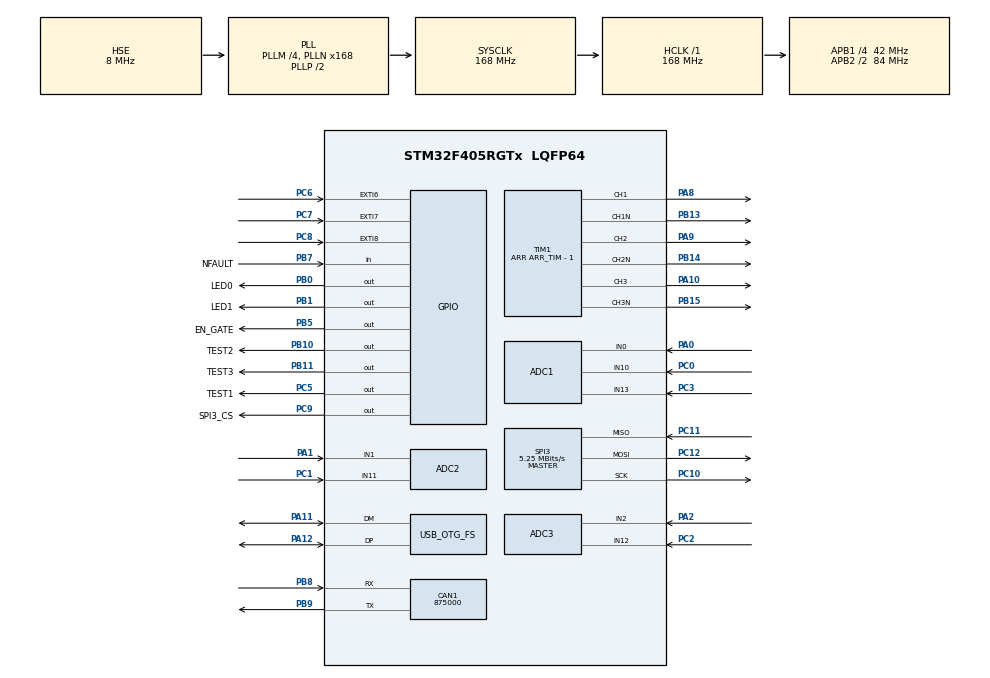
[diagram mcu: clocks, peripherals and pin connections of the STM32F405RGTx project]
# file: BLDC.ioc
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ADC1.Channel-0\#ChannelRegularConversion=ADC_CHANNEL_13
ADC1.Channel-1\#ChannelInjectedConversion=ADC_CHANNEL_10
ADC1.Channel-4\#ChannelInjectedConversion=ADC_CHANNEL_0
ADC1.ContinuousConvMode=ENABLE
ADC1.DMAContinuousRequests=ENABLE
ADC1.ExternalTrigInjecConv=ADC_EXTERNALTRIGINJECCONV_T1_TRGO
ADC1.InjNumberOfConversion=2
ADC1.InjectedOffset-1\#ChannelInjectedConversion=0
ADC1.InjectedOffset-4\#ChannelInjectedConversion=0
ADC1.InjectedRank-1\#ChannelInjectedConversion=1
ADC1.InjectedRank-4\#ChannelInjectedConversion=2
ADC1.Mode=ADC_TRIPLEMODE_INJECSIMULT
ADC1.NbrOfConversion=1
ADC1.NbrOfConversionFlag=1
ADC1.Rank-0\#ChannelRegularConversion=1
ADC1.SamplingTime-0\#ChannelRegularConversion=ADC_SAMPLETIME_480CYCLES
ADC1.SamplingTime-1\#ChannelInjectedConversion=ADC_SAMPLETIME_15CYCLES
ADC1.SamplingTime-4\#ChannelInjectedConversion=ADC_SAMPLETIME_15CYCLES
ADC1.master=1
ADC2.Channel-0\#ChannelRegularConversion=ADC_CHANNEL_1
ADC2.Channel-1\#ChannelInjectedConversion=ADC_CHANNEL_11
ADC2.Channel-4\#ChannelInjectedConversion=ADC_CHANNEL_1
ADC2.InjNumberOfConversion=2
ADC2.InjectedOffset-1\#ChannelInjectedConversion=0
ADC2.InjectedOffset-4\#ChannelInjectedConversion=0
ADC2.InjectedRank-1\#ChannelInjectedConversion=1
ADC2.InjectedRank-4\#ChannelInjectedConversion=2
ADC2.Mode=ADC_TRIPLEMODE_INJECSIMULT
ADC2.NbrOfConversion=1
ADC2.NbrOfConversionFlag=1
ADC2.Rank-0\#ChannelRegularConversion=1
ADC2.SamplingTime-0\#ChannelRegularConversion=ADC_SAMPLETIME_3CYCLES
ADC2.SamplingTime-1\#ChannelInjectedConversion=ADC_SAMPLETIME_15CYCLES
ADC2.SamplingTime-4\#ChannelInjectedConversion=ADC_SAMPLETIME_15CYCLES
ADC3.Channel-1\#ChannelRegularConversion=ADC_CHANNEL_2
ADC3.Channel-2\#ChannelInjectedConversion=ADC_CHANNEL_12
ADC3.Channel-3\#ChannelInjectedConversion=ADC_CHANNEL_2
ADC3.DMAContinuousRequests=DISABLE
ADC3.InjNumberOfConversion=2
ADC3.InjectedOffset-2\#ChannelInjectedConversion=0
ADC3.InjectedOffset-3\#ChannelInjectedConversion=0
ADC3.InjectedRank-2\#ChannelInjectedConversion=1
ADC3.InjectedRank-3\#ChannelInjectedConversion=2
ADC3.NbrOfConversionFlag=1
ADC3.Rank-1\#ChannelRegularConversion=1
ADC3.SamplingTime-1\#ChannelRegularConversion=ADC_SAMPLETIME_84CYCLES
ADC3.SamplingTime-2\#ChannelInjectedConversion=ADC_SAMPLETIME_15CYCLES
ADC3.SamplingTime-3\#ChannelInjectedConversion=ADC_SAMPLETIME_15CYCLES
CAN1.CalculateBaudRate=875000
CAN1.CalculateTimeBit=1142
CAN1.CalculateTimeQuantum=380.95238095238096
Dma.ADC1.1.Direction=DMA_PERIPH_TO_MEMORY
Dma.ADC1.1.FIFOMode=DMA_FIFOMODE_DISABLE
Dma.ADC1.1.Instance=DMA2_Stream4
Dma.ADC1.1.MemDataAlignment=DMA_MDATAALIGN_HALFWORD
Dma.ADC1.1.MemInc=DMA_MINC_ENABLE
Dma.ADC1.1.Mode=DMA_CIRCULAR
Dma.ADC1.1.PeriphDataAlignment=DMA_PDATAALIGN_HALFWORD
Dma.ADC1.1.PeriphInc=DMA_PINC_DISABLE
Dma.ADC1.1.Priority=DMA_PRIORITY_LOW
Dma.ADC3.0.Direction=DMA_PERIPH_TO_MEMORY
Dma.ADC3.0.FIFOMode=DMA_FIFOMODE_DISABLE
Dma.ADC3.0.Instance=DMA2_Stream0
Dma.ADC3.0.MemDataAlignment=DMA_MDATAALIGN_HALFWORD
Dma.ADC3.0.MemInc=DMA_MINC_ENABLE
Dma.ADC3.0.Mode=DMA_CIRCULAR
Dma.ADC3.0.PeriphDataAlignment=DMA_PDATAALIGN_HALFWORD
Dma.ADC3.0.PeriphInc=DMA_PINC_DISABLE
Dma.ADC3.0.Priority=DMA_PRIORITY_LOW
Dma.Request0=ADC3
Dma.Request1=ADC1
FREERTOS.Tasks01=Task01,24,256,StartTask01,As weak,NULL,Dynamic,NULL,NULL;Task02,8,256,StartTask02,As weak,NULL,Dynamic,NULL,NULL;Task03,8,256,StartTask03,As weak,NULL,Dynamic,NULL,NULL
FREERTOS.configENABLE_FPU=1
FREERTOS.configUSE_NEWLIB_REENTRANT=1
Mcu.Family=STM32F4
Mcu.Name=STM32F405RGTx
Mcu.Package=LQFP64
Mcu.UserConstants=ARR_TIM,2000
NVIC.ADC_IRQn=true\:5\:0\:false\:false\:true\:true\:true\:true\:true
NVIC.DMA2_Stream0_IRQn=true\:5\:0\:false\:false\:true\:true\:false\:true\:true
NVIC.DMA2_Stream4_IRQn=true\:5\:0\:false\:false\:true\:true\:false\:true\:true
NVIC.EXTI9_5_IRQn=true\:5\:0\:false\:false\:true\:true\:true\:true\:true
NVIC.OTG_FS_IRQn=true\:5\:0\:false\:false\:true\:true\:false\:true\:true
NVIC.PriorityGroup=NVIC_PRIORITYGROUP_4
NVIC.TIM1_CC_IRQn=true\:5\:0\:false\:false\:true\:true\:true\:true\:true
NVIC.TIM8_TRG_COM_TIM14_IRQn=true\:15\:0\:false\:false\:true\:false\:false\:true\:true
NVIC.TimeBase=TIM8_TRG_COM_TIM14_IRQn
NVIC.TimeBaseIP=TIM14
PA0-WKUP.Signal=ADCx_IN0
PA1.Signal=ADCx_IN1
PA10.Signal=S_TIM1_CH3
PA11.Mode=Device_Only
PA11.Signal=USB_OTG_FS_DM
PA12.Mode=Device_Only
PA12.Signal=USB_OTG_FS_DP
PA13.Mode=Serial_Wire
PA13.Signal=SYS_JTMS-SWDIO
PA14.Mode=Serial_Wire
PA14.Signal=SYS_JTCK-SWCLK
PA2.Signal=ADCx_IN2
PA8.Signal=S_TIM1_CH1
PA9.Signal=S_TIM1_CH2
PB0.GPIO_Label=LED0
PB0.Signal=GPIO_Output
PB1.GPIO_Label=LED1
PB1.Signal=GPIO_Output
PB10.GPIO_Label=TEST2
PB10.Signal=GPIO_Output
PB11.GPIO_Label=TEST3
PB11.Signal=GPIO_Output
PB13.Mode=PWM Generation1 CH1 CH1N
PB13.Signal=TIM1_CH1N
PB14.Mode=PWM Generation2 CH2 CH2N
PB14.Signal=TIM1_CH2N
PB15.Mode=PWM Generation3 CH3 CH3N
PB15.Signal=TIM1_CH3N
PB5.GPIO_Label=EN_GATE
PB5.Signal=GPIO_Output
PB7.GPIO_Label=NFAULT
PB7.GPIO_PuPd=GPIO_PULLUP
PB7.Signal=GPIO_Input
PB8.Mode=CAN_Activate
PB8.Signal=CAN1_RX
PB9.Mode=CAN_Activate
PB9.Signal=CAN1_TX
PC0.Signal=ADCx_IN10
PC1.Signal=ADCx_IN11
PC10.Mode=Full_Duplex_Master
PC10.Signal=SPI3_SCK
PC11.Mode=Full_Duplex_Master
PC11.Signal=SPI3_MISO
PC12.Mode=Full_Duplex_Master
PC12.Signal=SPI3_MOSI
PC2.Signal=ADCx_IN12
PC3.Signal=ADCx_IN13
PC5.GPIO_Label=TEST1
PC5.Signal=GPIO_Output
PC6.GPIO_ModeDefaultEXTI=GPIO_MODE_IT_RISING_FALLING
PC6.Signal=GPXTI6
PC7.GPIO_ModeDefaultEXTI=GPIO_MODE_IT_RISING_FALLING
PC7.Signal=GPXTI7
PC8.GPIO_ModeDefaultEXTI=GPIO_MODE_IT_RISING_FALLING
PC8.Signal=GPXTI8
PC9.GPIO_Label=SPI3_CS
PC9.GPIO_Speed=GPIO_SPEED_FREQ_MEDIUM
PC9.PinState=GPIO_PIN_SET
PC9.Signal=GPIO_Output
PH0-OSC_IN.Mode=HSE-External-Oscillator
PH0-OSC_IN.Signal=RCC_OSC_IN
PH1-OSC_OUT.Mode=HSE-External-Oscillator
PH1-OSC_OUT.Signal=RCC_OSC_OUT
ProjectManager.HeapSize=0x600
ProjectManager.StackSize=0x600
ProjectManager.TargetToolchain=STM32CubeIDE
RCC.48MHZClocksFreq_Value=48000000
RCC.AHBFreq_Value=168000000
RCC.APB1CLKDivider=RCC_HCLK_DIV4
RCC.APB1Freq_Value=42000000
RCC.APB1TimFreq_Value=84000000
RCC.APB2CLKDivider=RCC_HCLK_DIV2
RCC.APB2Freq_Value=84000000
RCC.APB2TimFreq_Value=168000000
RCC.CortexFreq_Value=168000000
RCC.HCLKFreq_Value=168000000
RCC.HSE_VALUE=8000000
RCC.HSI_VALUE=16000000
RCC.LSE_VALUE=32768
RCC.PLLM=4
RCC.PLLN=168
RCC.PLLQ=7
RCC.SYSCLKFreq_VALUE=168000000
RCC.SYSCLKSource=RCC_SYSCLKSOURCE_PLLCLK
RCC.VCOOutputFreq_Value=336000000
SH.ADCx_IN0.0=ADC1_IN0,IN0
SH.ADCx_IN1.0=ADC2_IN1,IN1
SH.ADCx_IN10.0=ADC1_IN10,IN10
SH.ADCx_IN11.0=ADC2_IN11,IN11
SH.ADCx_IN12.0=ADC3_IN12,IN12
SH.ADCx_IN13.0=ADC1_IN13,IN13
SH.ADCx_IN2.0=ADC3_IN2,IN2
SH.S_TIM1_CH1.0=TIM1_CH1,PWM Generation1 CH1 CH1N
SH.S_TIM1_CH2.0=TIM1_CH2,PWM Generation2 CH2 CH2N
SH.S_TIM1_CH3.0=TIM1_CH3,PWM Generation3 CH3 CH3N
SPI3.BaudRatePrescaler=SPI_BAUDRATEPRESCALER_8
SPI3.CLKPhase=SPI_PHASE_2EDGE
SPI3.CalculateBaudRate=5.25 MBits/s
SPI3.DataSize=SPI_DATASIZE_16BIT
SPI3.Direction=SPI_DIRECTION_2LINES
SPI3.Mode=SPI_MODE_MASTER
SPI3.VirtualType=VM_MASTER
TIM1.AutoReloadPreload=TIM_AUTORELOAD_PRELOAD_ENABLE
TIM1.Channel-PWM\ Generation1\ CH1\ CH1N=TIM_CHANNEL_1
TIM1.Channel-PWM\ Generation2\ CH2\ CH2N=TIM_CHANNEL_2
TIM1.Channel-PWM\ Generation3\ CH3\ CH3N=TIM_CHANNEL_3
TIM1.Channel-PWM\ Generation4\ No\ Output=TIM_CHANNEL_4
TIM1.CounterMode=TIM_COUNTERMODE_CENTERALIGNED1
TIM1.DeadTime=40
TIM1.OCMode_PWM-PWM\ Generation4\ No\ Output=TIM_OCMODE_PWM2
TIM1.Period=ARR_TIM - 1
TIM1.Pulse-PWM\ Generation4\ No\ Output=ARR_TIM - 61
TIM1.TIM_MasterOutputTrigger=TIM_TRGO_OC4REF
TIM1.TIM_MasterSlaveMode=TIM_MASTERSLAVEMODE_DISABLE
USB_DEVICE.CLASS_NAME_FS=CDC
USB_DEVICE.VirtualMode-CDC_FS=Cdc
USB_DEVICE.VirtualModeFS=Cdc_FS
USB_OTG_FS.VirtualMode=Device_Only
VP_FREERTOS_VS_CMSIS_V2.Mode=CMSIS_V2
VP_SYS_VS_tim14.Mode=TIM14
VP_TIM1_VS_ClockSourceINT.Mode=Internal
VP_TIM1_VS_no_output4.Mode=PWM Generation4 No Output
VP_USB_DEVICE_VS_USB_DEVICE_CDC_FS.Mode=CDC_FS
board=custom

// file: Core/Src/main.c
/* USER CODE BEGIN Header */
/**
  ******************************************************************************
  * @file           : main.c
  * @brief          : Main program body
  ******************************************************************************
  * @attention
  *
  * Copyright (c) 2026 STMicroelectronics.
  * All rights reserved.
  *
  * This software is licensed under terms that can be found in the LICENSE file
  * in the root directory of this software component.
  * If no LICENSE file comes with this software, it is provided AS-IS.
  *
  ******************************************************************************
  */
/* USER CODE END Header */
#include "main.h"
#include "cmsis_os.h"
#include "adc.h"
#include "can.h"
#include "dma.h"
#include "spi.h"
#include "tim.h"
#include "usb_device.h"
#include "gpio.h"

void SystemClock_Config(void);
void MX_FREERTOS_Init(void);

int main(void)
{

  /* MCU Configuration--------------------------------------------------------*/

  /* Reset of all peripherals, Initializes the Flash interface and the Systick. */
  HAL_Init();

  /* Configure the system clock */
  SystemClock_Config();

  /* Initialize all configured peripherals */
  MX_GPIO_Init();
  MX_DMA_Init();
  MX_ADC1_Init();
  MX_ADC3_Init();
  MX_CAN1_Init();
  MX_SPI3_Init();
  MX_TIM1_Init();
  MX_ADC2_Init();

  /* Init scheduler */
  osKernelInitialize();  /* Call init function for freertos objects (in cmsis_os2.c) */
  MX_FREERTOS_Init();

  /* Start scheduler */
  osKernelStart();

  /* We should never get here as control is now taken by the scheduler */

  /* Infinite loop */
  while (1)
  {

    /* USER CODE BEGIN 3 */
	  HAL_GPIO_TogglePin(LED1_GPIO_Port, LED1_Pin);
	  HAL_Delay(500);
  }
  /* USER CODE END 3 */
}

void SystemClock_Config(void)
{
  RCC_OscInitTypeDef RCC_OscInitStruct = {0};
  RCC_ClkInitTypeDef RCC_ClkInitStruct = {0};

  /** Configure the main internal regulator output voltage
  */
  __HAL_RCC_PWR_CLK_ENABLE();
  __HAL_PWR_VOLTAGESCALING_CONFIG(PWR_REGULATOR_VOLTAGE_SCALE1);

  /** Initializes the RCC Oscillators according to the specified parameters
  * in the RCC_OscInitTypeDef structure.
  */
  RCC_OscInitStruct.OscillatorType = RCC_OSCILLATORTYPE_HSE;
  RCC_OscInitStruct.HSEState = RCC_HSE_ON;
  RCC_OscInitStruct.PLL.PLLState = RCC_PLL_ON;
  RCC_OscInitStruct.PLL.PLLSource = RCC_PLLSOURCE_HSE;
  RCC_OscInitStruct.PLL.PLLM = 4;
  RCC_OscInitStruct.PLL.PLLN = 168;
  RCC_OscInitStruct.PLL.PLLP = RCC_PLLP_DIV2;
  RCC_OscInitStruct.PLL.PLLQ = 7;
  if (HAL_RCC_OscConfig(&RCC_OscInitStruct) != HAL_OK)
  {
    Error_Handler();
  }

  /** Initializes the CPU, AHB and APB buses clocks
  */
  RCC_ClkInitStruct.ClockType = RCC_CLOCKTYPE_HCLK|RCC_CLOCKTYPE_SYSCLK
                              |RCC_CLOCKTYPE_PCLK1|RCC_CLOCKTYPE_PCLK2;
  RCC_ClkInitStruct.SYSCLKSource = RCC_SYSCLKSOURCE_PLLCLK;
  RCC_ClkInitStruct.AHBCLKDivider = RCC_SYSCLK_DIV1;
  RCC_ClkInitStruct.APB1CLKDivider = RCC_HCLK_DIV4;
  RCC_ClkInitStruct.APB2CLKDivider = RCC_HCLK_DIV2;

  if (HAL_RCC_ClockConfig(&RCC_ClkInitStruct, FLASH_LATENCY_5) != HAL_OK)
  {
    Error_Handler();
  }
}

void HAL_TIM_PeriodElapsedCallback(TIM_HandleTypeDef *htim)
{
  if (htim->Instance == TIM14)
  {
    HAL_IncTick();
  }
}

void Error_Handler(void)
{
  __disable_irq();
  while (1)
  {
  }
}

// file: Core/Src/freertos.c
/* USER CODE BEGIN Header */
/**
  ******************************************************************************
  * File Name          : freertos.c
  * Description        : Code for freertos applications
  ******************************************************************************
  * @attention
  *
  * Copyright (c) 2026 STMicroelectronics.
  * All rights reserved.
  *
  * This software is licensed under terms that can be found in the LICENSE file
  * in the root directory of this software component.
  * If no LICENSE file comes with this software, it is provided AS-IS.
  *
  ******************************************************************************
  */
/* USER CODE END Header */

#include "FreeRTOS.h"
#include "task.h"
#include "main.h"
#include "cmsis_os.h"

/* Definitions for Task01 */
osThreadId_t Task01Handle;
const osThreadAttr_t Task01_attributes = {
  .name = "Task01",
  .stack_size = 256 * 4,
  .priority = (osPriority_t) osPriorityNormal,
};
/* Definitions for Task02 */
osThreadId_t Task02Handle;
const osThreadAttr_t Task02_attributes = {
  .name = "Task02",
  .stack_size = 256 * 4,
  .priority = (osPriority_t) osPriorityLow,
};
/* Definitions for Task03 */
osThreadId_t Task03Handle;
const osThreadAttr_t Task03_attributes = {
  .name = "Task03",
  .stack_size = 256 * 4,
  .priority = (osPriority_t) osPriorityLow,
};

void StartTask01(void *argument);
void StartTask02(void *argument);
void StartTask03(void *argument);

extern void MX_USB_DEVICE_Init(void);
void MX_FREERTOS_Init(void); /* (MISRA C 2004 rule 8.1) */

void MX_FREERTOS_Init(void) {

  /* Create the thread(s) */
  /* creation of Task01 */
  Task01Handle = osThreadNew(StartTask01, NULL, &Task01_attributes);

  /* creation of Task02 */
  Task02Handle = osThreadNew(StartTask02, NULL, &Task02_attributes);

  /* creation of Task03 */
  Task03Handle = osThreadNew(StartTask03, NULL, &Task03_attributes);

}

__weak void StartTask01(void *argument)
{
  /* init code for USB_DEVICE */
  MX_USB_DEVICE_Init();
  for(;;)
  {
    osDelay(1);
  }
}

__weak void StartTask02(void *argument)
{
  for(;;)
  {
    osDelay(1);
  }
}

__weak void StartTask03(void *argument)
{
  for(;;)
  {
    osDelay(1);
  }
}
